# N32G41x register map
Vendor: Nsingtech Ltd.; File version: 1.0
CPU: CM4 r0p1, little endian, no MPU, no FPU, 4 interrupt priority bits
Registers are 32-bit, read-write, reset 0x0 unless marked. A register's access mark holds for its fields unless they carry their own. Offsets are from the block's base; [hi:lo] are bit positions; {n}, {i} and the like mark numbered series; 'fields as' and 'values as' point back to an identical list.

## CRC — CRC Calculation Unit
Base 0x40023000
0x00 CRC_CRC32CTRL wo — CRC32 Control Register
  [0] RESET — CRC32 reset control
0x04 CRC_CRC32DAT reset 0xFFFFFFFF — CRC32 Data Input Register
  [31:0] CRC32DAT — Data register (write: input, read: CRC result)
0x08 CRC_CRC32IDAT — CRC32 Independent Data Register
  [7:0] CRC32IDAT — General-purpose 8-bit data register
0x0C CRC_CRC32D reset 0xFFFFFFFF — CRC32 Result Register
  [31:0] CRC32D — CRC32 calculation result
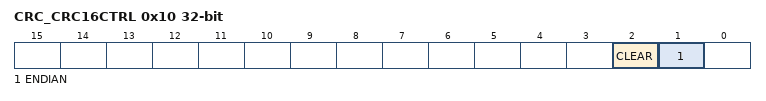
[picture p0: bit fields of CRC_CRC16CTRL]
0x10 CRC_CRC16CTRL — CRC16 Control Register
  [2] CLEAR wo — Clear CRC16 result register
  [1] ENDIAN — Data endianness
0x14 CRC_CRC16DAT — CRC16 Data Register
  [7:0] CRC16DAT — CRC16 input data
0x18 CRC_CRC16D — CRC16 Result Register
  [15:0] CRC16D — CRC16 calculation result
0x1C CRC_LRC — LRC Result Register
  [7:0] LRCDAT — LRC check value

## DMA — Direct Memory Access Controller
Base 0x40020000
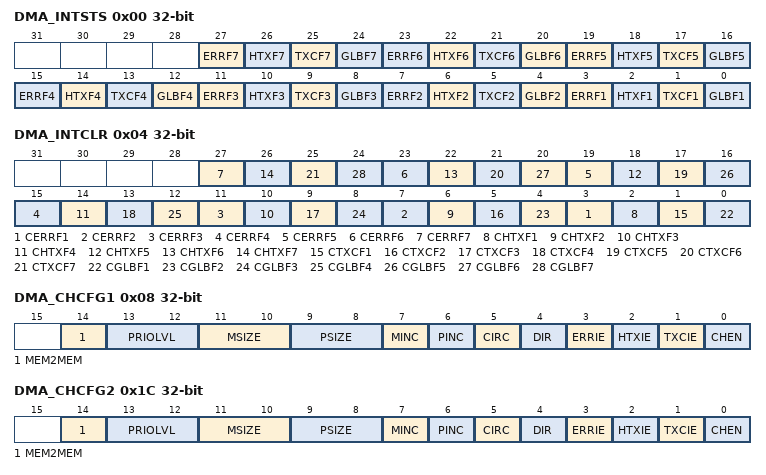
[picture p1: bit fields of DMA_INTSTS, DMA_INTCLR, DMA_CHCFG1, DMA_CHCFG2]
0x00 DMA_INTSTS ro — DMA Interrupt Status Register
  [4n-1] ERRF{n} (n=1..7) — Transfer error flag for channel {n}
  [4n-2] HTXF{n} (n=1..7) — Half transfer flag for channel {n}
  [4n-3] TXCF{n} (n=1..7) — Transfer complete flag for channel {n}
  [4n-4] GLBF{n} (n=1..7) — Global flag for channel {n}
0x04 DMA_INTCLR wo — DMA Interrupt Flag Clear Register
  [4n-1] CERRF{n} (n=1..7) — Clear transfer error flag for channel {n}
  [4n-2] CHTXF{n} (n=1..7) — Clear half transfer flag for channel {n}
  [4n-3] CTXCF{n} (n=1..7) — Clear transfer complete flag for channel {n}
  [4n-4] CGLBF{n} (n=1..7) — Clear global flag for channel {n}
0x08 DMA_CHCFG1 — DMA Channel 1 Configuration Register
  [14] MEM2MEM — Memory to memory mode
  [13:12] PRIOLVL — Channel priority
  [11:10] MSIZE — Memory data size
  [9:8] PSIZE — Peripheral data size
  [7] MINC — Memory address increment mode
  [6] PINC — Peripheral address increment mode
  [5] CIRC — Circular mode
  [4] DIR — Data transfer direction
  [3] ERRIE — Transfer error interrupt enable
  [2] HTXIE — Half transfer interrupt enable
  [1] TXCIE — Transfer complete interrupt enable
  [0] CHEN — Channel enable
0x0C DMA_TXNUM1 — DMA Channel 1 Transfer Number Register
  [15:0] NDTX — Number of data to transfer
0x10 DMA_PADDR1 — DMA Channel 1 Peripheral Address Register
  [31:0] ADDR — Peripheral base address
{0x0+0x14*i} DMA_MADDR{i} (i=1..7) — DMA Channel {i} Memory Address Register
  [31:0] ADDR — Memory base address
{0x4+0x14*i} DMA_CHSEL{i} (i=1..7) — DMA Channel {i} Request Selection Register
  [5:0] CH_SEL — DMA channel request source selection
0x1C DMA_CHCFG2 — DMA Channel 2 Configuration Register
  fields as DMA_CHCFG1
0x20 DMA_TXNUM2 — DMA Channel 2 Transfer Number Register
  [15:0] NDTX — Number of data to transfer
0x24 DMA_PADDR2 — DMA Channel 2 Peripheral Address Register
  [31:0] ADDR — Peripheral base address
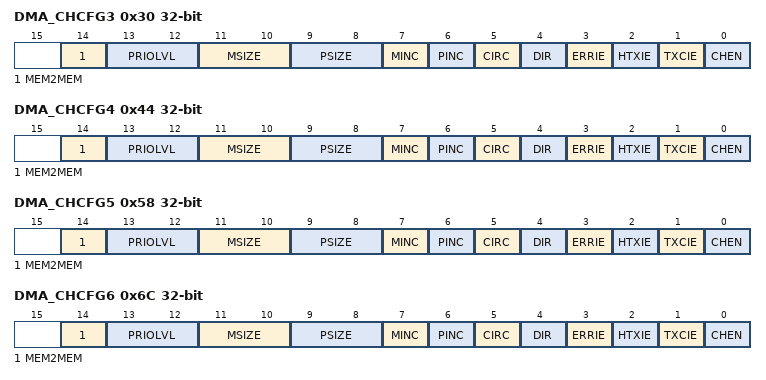
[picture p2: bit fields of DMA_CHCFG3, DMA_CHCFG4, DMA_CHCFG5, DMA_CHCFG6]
0x30 DMA_CHCFG3 — DMA Channel 3 Configuration Register
  fields as DMA_CHCFG1
0x34 DMA_TXNUM3 — DMA Channel 3 Transfer Number Register
  [15:0] NDTX — Number of data to transfer
0x38 DMA_PADDR3 — DMA Channel 3 Peripheral Address Register
  [31:0] ADDR — Peripheral base address
0x44 DMA_CHCFG4 — DMA Channel 4 Configuration Register
  fields as DMA_CHCFG1
0x48 DMA_TXNUM4 — DMA Channel 4 Transfer Number Register
  [15:0] NDTX — Number of data to transfer
0x4C DMA_PADDR4 — DMA Channel 4 Peripheral Address Register
  [31:0] ADDR — Peripheral base address
0x58 DMA_CHCFG5 — DMA Channel 5 Configuration Register
  fields as DMA_CHCFG1
0x5C DMA_TXNUM5 — DMA Channel 5 Transfer Number Register
  [15:0] NDTX — Number of data to transfer
0x60 DMA_PADDR5 — DMA Channel 5 Peripheral Address Register
  [31:0] ADDR — Peripheral base address
0x6C DMA_CHCFG6 — DMA Channel 6 Configuration Register
  fields as DMA_CHCFG1
0x70 DMA_TXNUM6 — DMA Channel 6 Transfer Number Register
  [15:0] NDTX — Number of data to transfer
0x74 DMA_PADDR6 — DMA Channel 6 Peripheral Address Register
  [31:0] ADDR — Peripheral base address
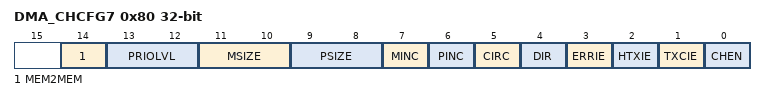
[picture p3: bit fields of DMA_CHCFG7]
0x80 DMA_CHCFG7 — DMA Channel 7 Configuration Register
  fields as DMA_CHCFG1
0x84 DMA_TXNUM7 — DMA Channel 7 Transfer Number Register
  [15:0] NDTX — Number of data to transfer
0x88 DMA_PADDR7 — DMA Channel 7 Peripheral Address Register
  [31:0] ADDR — Peripheral base address
